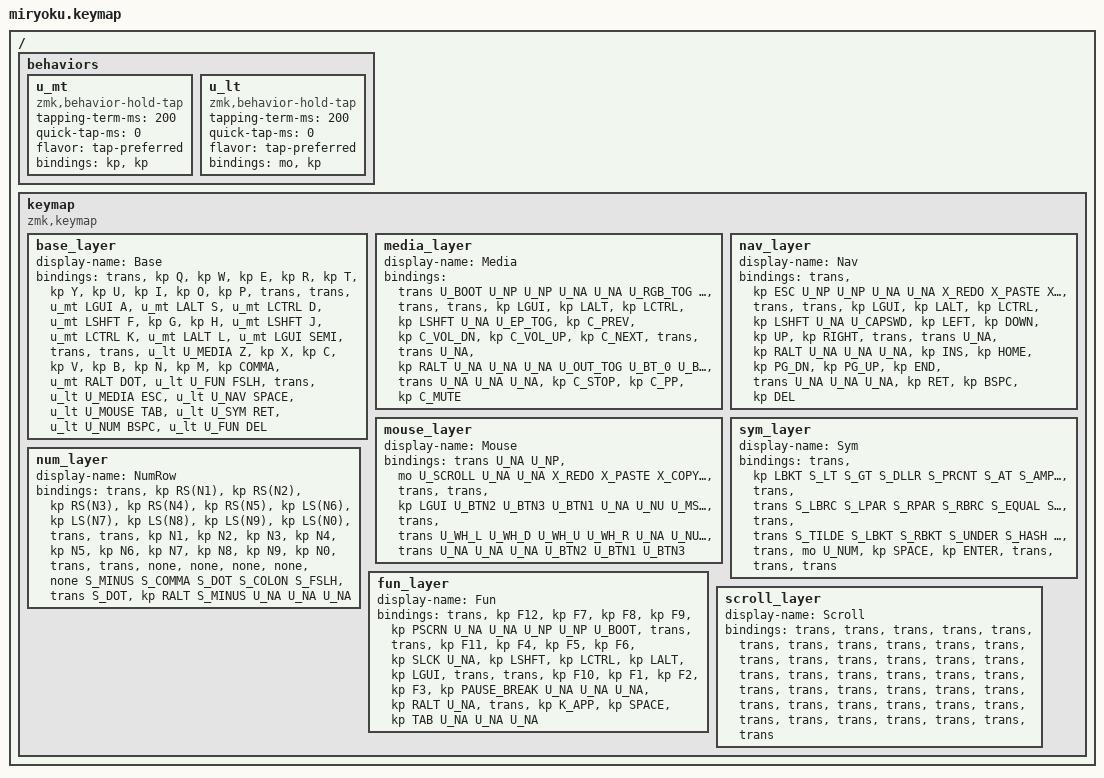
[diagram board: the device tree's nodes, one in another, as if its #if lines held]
// Miryoku keymap for the Quacken
// Adapted from https://github.com/manna-harbour/miryoku
// Reference port: https://github.com/jb-flamant/miryoku_zmk

#ifndef CI_IGNORE_USER_SETTINGS
  #include "settings.h"
#endif

#include "aliases.h"
#include "mappings.dtsi"

#include <dt-bindings/zmk/bt.h>
#include <dt-bindings/zmk/outputs.h>
#include <dt-bindings/zmk/pointing.h>

// To enable RGB controls on the Media layer, also include <dt-bindings/zmk/rgb.h>
// and replace the U_RGB_* defines below with `&rgb_ug RGB_*` (needs RGB hardware
// and CONFIG_ZMK_RGB_UNDERGLOW=y). The Quacken has no RGB hardware so we no-op.
//
// Mouse keys on the Mouse layer require CONFIG_ZMK_POINTING=y (set in build.yaml).

// Layer indices (Miryoku canon)
#include "miryoku_layers.h"

// Miryoku helper aliases → ZMK built-ins
#define U_NA       &none
#define U_NP       &none
#define U_NU       &none
#define U_BOOT     &bootloader
#define U_EP_TOG   &out OUT_TOG
#define U_OUT_TOG  &out OUT_TOG
#define U_BT_0     &bt BT_SEL 0
#define U_BT_1     &bt BT_SEL 1
#define U_BT_2     &bt BT_SEL 2
#define U_BT_3     &bt BT_SEL 3
#define U_CAPSWD   &caps_word

// RGB (no hardware on Quacken -- placeholders)
#define U_RGB_TOG  &none
#define U_RGB_EFF  &none
#define U_RGB_HUI  &none
#define U_RGB_SAI  &none
#define U_RGB_BRI  &none

// Mouse keys
#define U_MS_L     &mmv MOVE_LEFT
#define U_MS_R     &mmv MOVE_RIGHT
#define U_MS_U     &mmv MOVE_UP
#define U_MS_D     &mmv MOVE_DOWN
#define U_WH_L     &msc SCRL_LEFT
#define U_WH_R     &msc SCRL_RIGHT
#define U_WH_U     &msc SCRL_UP
#define U_WH_D     &msc SCRL_DOWN
#define U_BTN1     &mkp LCLK
#define U_BTN2     &mkp RCLK
#define U_BTN3     &mkp MCLK

/ {
  behaviors {
    // Home row mod: tap-preferred, Miryoku default timing
    u_mt: u_mt {
      compatible = "zmk,behavior-hold-tap";
      #binding-cells = <2>;
      tapping-term-ms = <200>;
      quick-tap-ms = <0>;
      flavor = "tap-preferred";
      bindings = <&kp>, <&kp>;
    };

    // Thumb layer-tap: tap-preferred
    u_lt: u_lt {
      compatible = "zmk,behavior-hold-tap";
      #binding-cells = <2>;
      tapping-term-ms = <200>;
      quick-tap-ms = <0>;
      flavor = "tap-preferred";
      bindings = <&mo>, <&kp>;
    };
  };

  keymap {
    compatible = "zmk,keymap";

    // 0. BASE -- QWERTY scancodes (typed via host AZERTY) + GACS home row mods
    //         -- bottom corners: hold W (Z) for Media, hold ! (FSLH) for Fun
    base_layer: base_layer {
      display-name = "Base";
      bindings = <
        &trans    &kp Q         &kp W         &kp E         &kp R         &kp T          &kp Y &kp U         &kp I         &kp O           &kp P            &trans
        &trans    &u_mt LGUI A  &u_mt LALT S  &u_mt LCTRL D &u_mt LSHFT F &kp G          &kp H &u_mt LSHFT J &u_mt LCTRL K &u_mt LALT L    &u_mt LGUI SEMI  &trans
        &trans    &u_lt U_MEDIA Z &kp X         &kp C         &kp V         &kp B          &kp N &kp M         &kp COMMA     &u_mt RALT DOT  &u_lt U_FUN FSLH &trans
                              &u_lt U_MEDIA ESC  &u_lt U_NAV SPACE  &u_lt U_MOUSE TAB     &u_lt U_SYM RET    &u_lt U_NUM BSPC  &u_lt U_FUN DEL
      >;
    };

    // 1. MEDIA -- RGB / consumer media / BT profiles (left thumb outer held)
    media_layer: media_layer {
      display-name = "Media";
      bindings = <
        &trans  U_BOOT      U_NP        U_NP        U_NA  U_NA       U_RGB_TOG  U_RGB_EFF    U_RGB_HUI    U_RGB_SAI    U_RGB_BRI  &trans
        &trans  &kp LGUI    &kp LALT    &kp LCTRL   &kp LSHFT   U_NA       U_EP_TOG   &kp C_PREV   &kp C_VOL_DN &kp C_VOL_UP &kp C_NEXT &trans
        &trans  U_NA        &kp RALT    U_NA   U_NA U_NA       U_OUT_TOG  U_BT_0       U_BT_1       U_BT_2       U_BT_3     &trans
                                        U_NA        U_NA        U_NA       &kp C_STOP &kp C_PP     &kp C_MUTE
      >;
    };

    // 2. NAV -- clipboard + arrow cluster + caps word (left thumb middle held)
    nav_layer: nav_layer {
      display-name = "Nav";
      bindings = <
        &trans  &kp ESC         U_NP        U_NP        U_NA  U_NA       X_REDO     X_PASTE      X_COPY       X_CUT        X_UNDO     &trans
        &trans  &kp LGUI    &kp LALT    &kp LCTRL   &kp LSHFT   U_NA       U_CAPSWD   &kp LEFT     &kp DOWN     &kp UP       &kp RIGHT  &trans
        &trans  U_NA        &kp RALT    U_NA   U_NA   U_NA       &kp INS    &kp HOME     &kp PG_DN    &kp PG_UP    &kp END    &trans
                                        U_NA        U_NA        U_NA       &kp RET    &kp BSPC     &kp DEL
      >;
    };

    // 3. MOUSE -- pointer / scroll / buttons (left thumb inner held)
    //          -- clicks on the left home row: S = right, D = middle, F = left
    //          -- hold E: trackball scrolls (Scroll layer)
    mouse_layer: mouse_layer {
      display-name = "Mouse";
      bindings = <
        &trans  U_NA        U_NP        &mo U_SCROLL U_NA        U_NA       X_REDO     X_PASTE      X_COPY       X_CUT        X_UNDO     &trans
        &trans  &kp LGUI    U_BTN2      U_BTN3      U_BTN1      U_NA       U_NU       U_MS_L       U_MS_D       U_MS_U       U_MS_R     &trans
        &trans  U_WH_L      U_WH_D      U_WH_U      U_WH_R      U_NA       U_NU       U_WH_L       U_WH_D       U_WH_U       U_WH_R     &trans
                                        U_NA        U_NA        U_NA       U_BTN2     U_BTN1       U_BTN3
      >;
    };

    // 4. SYM -- Arsenik symbols across both hands (from Selenium quacken.keymap)
    //          -- caret is the AZERTY dead circumflex key (^ then e = ê)
    sym_layer: sym_layer {
      display-name = "Sym";
      bindings = <
        &trans  &kp LBKT S_LT    S_GT    S_DLLR  S_PRCNT  S_AT    S_AMPS  S_STAR  S_SQT   S_GRAVE  &trans
        &trans  S_LBRC  S_LPAR  S_RPAR  S_RBRC  S_EQUAL  S_BSLH  S_PLUS  S_MINUS S_FSLH  S_DQT    &trans
        &trans  S_TILDE S_LBKT  S_RBKT  S_UNDER S_HASH   S_PIPE  S_EXCL  S_SEMI  S_COLON S_QMARK  &trans
                                &mo U_NUM  &kp SPACE  &kp ENTER  &trans  &trans  &trans
      >;
    };

    // 5. NUM -- numpad Miryoku canon (default) OR Selenium-style NumRow (#define MIRYOKU_USE_NUMROW)
    num_layer: num_layer {
#ifdef MIRYOKU_USE_NUMROW
      display-name = "NumRow";
      bindings = <
        &trans  &kp RS(N1)  &kp RS(N2)  &kp RS(N3)  &kp RS(N4)  &kp RS(N5) &kp LS(N6) &kp LS(N7)   &kp LS(N8)   &kp LS(N9)   &kp LS(N0) &trans
        &trans  &kp N1      &kp N2      &kp N3      &kp N4      &kp N5     &kp N6     &kp N7       &kp N8       &kp N9       &kp N0     &trans
        &trans  &none       &none       &none       &none       &none      S_MINUS    S_COMMA      S_DOT        S_COLON      S_FSLH     &trans
                                        S_DOT       &kp RALT    S_MINUS    U_NA       U_NA         U_NA
      >;
#else
      display-name = "Num";
      bindings = <
        &trans  S_LBKT      S_N7        S_N8        S_N9        S_RBKT     U_NA       U_NA   U_NP         U_NP         U_BOOT     &trans
        &trans  S_SEMI      S_N4        S_N5        S_N6        S_EQUAL    U_NA       &kp LSHFT    &kp LCTRL    &kp LALT     &kp LGUI   &trans
        &trans  S_GRAVE     S_N1        S_N2        S_N3        S_BSLH     U_NA       U_NA    U_NA    &kp RALT     U_NA       &trans
                                        S_DOT       S_N0        S_MINUS    U_NA       U_NA         U_NA
      >;
#endif
    };

    // 6. FUN -- function keys + system (right thumb outer held)
    fun_layer: fun_layer {
      display-name = "Fun";
      bindings = <
        &trans  &kp F12     &kp F7      &kp F8      &kp F9      &kp PSCRN       U_NA  U_NA   U_NP         U_NP         U_BOOT     &trans
        &trans  &kp F11     &kp F4      &kp F5      &kp F6      &kp SLCK        U_NA  &kp LSHFT    &kp LCTRL    &kp LALT     &kp LGUI   &trans
        &trans  &kp F10     &kp F1      &kp F2      &kp F3      &kp PAUSE_BREAK U_NA  U_NA    U_NA  &kp RALT     U_NA       &trans
                                        &kp K_APP   &kp SPACE   &kp TAB         U_NA  U_NA         U_NA
      >;
    };

    // 7. SCROLL -- transparent, held with E on the Mouse layer: the trackball
    //           scrolls instead of moving the pointer (trackball_i2c.overlay)
    scroll_layer: scroll_layer {
      display-name = "Scroll";
      bindings = <
        &trans  &trans  &trans  &trans  &trans  &trans    &trans  &trans  &trans  &trans  &trans  &trans
        &trans  &trans  &trans  &trans  &trans  &trans    &trans  &trans  &trans  &trans  &trans  &trans
        &trans  &trans  &trans  &trans  &trans  &trans    &trans  &trans  &trans  &trans  &trans  &trans
                                &trans  &trans  &trans    &trans  &trans  &trans
      >;
    };
  };
};
